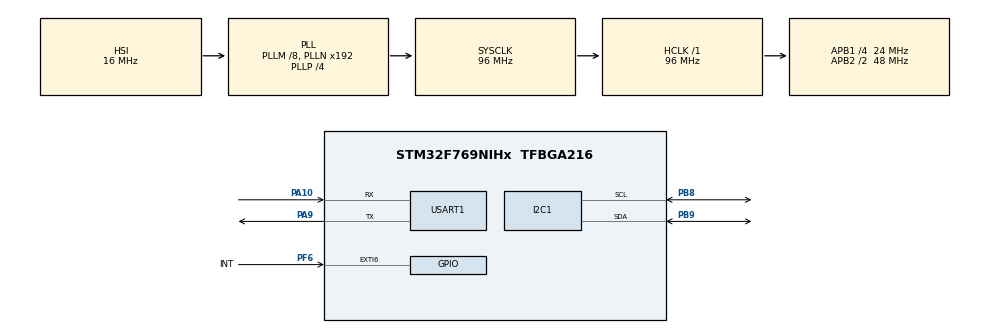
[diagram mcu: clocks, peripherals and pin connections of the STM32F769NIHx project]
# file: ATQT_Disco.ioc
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I2C1.Timing=0x00506682
Mcu.Family=STM32F7
Mcu.Name=STM32F769NIHx
Mcu.Package=TFBGA216
NVIC.EXTI9_5_IRQn=true\:0\:0\:false\:false\:true\:true\:true\:true
NVIC.PriorityGroup=NVIC_PRIORITYGROUP_4
NVIC.TIM5_IRQn=true\:0\:0\:false\:false\:true\:true\:true\:true
PA10.Mode=Asynchronous
PA10.Signal=USART1_RX
PA9.Mode=Asynchronous
PA9.Signal=USART1_TX
PB8.GPIO_Pu=GPIO_PULLUP
PB8.Mode=I2C
PB8.Signal=I2C1_SCL
PB9.GPIO_Pu=GPIO_PULLUP
PB9.Mode=I2C
PB9.Signal=I2C1_SDA
PF6.GPIO_Label=INT
PF6.GPIO_PuPd=GPIO_NOPULL
PF6.Signal=GPXTI6
PH0/OSC_IN.Mode=HSE-External-Oscillator
PH0/OSC_IN.Signal=RCC_OSC_IN
PH1/OSC_OUT.Mode=HSE-External-Oscillator
PH1/OSC_OUT.Signal=RCC_OSC_OUT
ProjectManager.HeapSize=0x200
ProjectManager.StackSize=0x400
ProjectManager.TargetToolchain=STM32CubeIDE
RCC.AHBFreq_Value=96000000
RCC.APB1CLKDivider=RCC_HCLK_DIV4
RCC.APB1Freq_Value=24000000
RCC.APB1TimFreq_Value=48000000
RCC.APB2CLKDivider=RCC_HCLK_DIV2
RCC.APB2Freq_Value=48000000
RCC.APB2TimFreq_Value=96000000
RCC.CortexFreq_Value=96000000
RCC.HCLKFreq_Value=96000000
RCC.HSE_VALUE=25000000
RCC.HSI_VALUE=16000000
RCC.LSE_VALUE=32768
RCC.PLLM=8
RCC.PLLP=RCC_PLLP_DIV4
RCC.PLLQ=4
RCC.PLLSAIQ=3
RCC.SYSCLKFreq_VALUE=96000000
RCC.SYSCLKSource=RCC_SYSCLKSOURCE_PLLCLK
RCC.USBFreq_Value=96000000
RCC.VCOOutputFreq_Value=384000000
TIM2.AutoReloadPreload=TIM_AUTORELOAD_PRELOAD_DISABLE
TIM2.Period=4294967296-1
TIM2.Prescaler=48000-1
TIM5.AutoReloadPreload=TIM_AUTORELOAD_PRELOAD_ENABLE
TIM5.Period=20-1
TIM5.Prescaler=48000-1
USART1.VirtualMode-Asynchronous=VM_ASYNC
VP_TIM2_VS_ClockSourceINT.Mode=Internal
VP_TIM5_VS_ClockSourceINT.Mode=Internal
board=STM32F769I-DISCO

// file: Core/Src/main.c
/* USER CODE BEGIN Header */
/**
  ******************************************************************************
  * @file           : main.c
  * @brief          : Main program body
  ******************************************************************************
  * @attention
  *
  * Copyright (c) 2022 STMicroelectronics.
  * All rights reserved.
  *
  * This software is licensed under terms that can be found in the LICENSE file
  * in the root directory of this software component.
  * If no LICENSE file comes with this software, it is provided AS-IS.
  *
  ******************************************************************************
  */
/* USER CODE END Header */
#include "main.h"
#include "i2c.h"
#include "tim.h"
#include "usart.h"
#include "gpio.h"

/* USER CODE BEGIN Includes */

//#include "Arg_mvp_Qtouch.h"

#include "at42qt2120.h"
/* USER CODE END Includes */

void SystemClock_Config(void);

int main(void)
{

  /* MCU Configuration--------------------------------------------------------*/

  /* Reset of all peripherals, Initializes the Flash interface and the Systick. */
  HAL_Init();

  /* Configure the system clock */
  SystemClock_Config();

  /* Initialize all configured peripherals */
  MX_GPIO_Init();
  MX_I2C1_Init();
  MX_USART1_UART_Init();
  MX_TIM2_Init();
  MX_TIM5_Init();
  /* USER CODE BEGIN 2 */

  //touch sensor init function
  touchSensor_Init();

 HAL_TIM_Base_Start(&htim2);
 HAL_TIM_Base_Start_IT(&htim5);

  /* printf("QTouch test\r\n");
   QTouch_Init();*/

  /* USER CODE END 2 */

  /* Infinite loop */
  while (1)
  {

	}
}

void SystemClock_Config(void)
{
  RCC_OscInitTypeDef RCC_OscInitStruct = {0};
  RCC_ClkInitTypeDef RCC_ClkInitStruct = {0};

  /** Configure the main internal regulator output voltage
  */
  __HAL_RCC_PWR_CLK_ENABLE();
  __HAL_PWR_VOLTAGESCALING_CONFIG(PWR_REGULATOR_VOLTAGE_SCALE3);

  /** Initializes the RCC Oscillators according to the specified parameters
  * in the RCC_OscInitTypeDef structure.
  */
  RCC_OscInitStruct.OscillatorType = RCC_OSCILLATORTYPE_HSI;
  RCC_OscInitStruct.HSIState = RCC_HSI_ON;
  RCC_OscInitStruct.HSICalibrationValue = RCC_HSICALIBRATION_DEFAULT;
  RCC_OscInitStruct.PLL.PLLState = RCC_PLL_ON;
  RCC_OscInitStruct.PLL.PLLSource = RCC_PLLSOURCE_HSI;
  RCC_OscInitStruct.PLL.PLLM = 8;
  RCC_OscInitStruct.PLL.PLLN = 192;
  RCC_OscInitStruct.PLL.PLLP = RCC_PLLP_DIV4;
  RCC_OscInitStruct.PLL.PLLQ = 4;
  RCC_OscInitStruct.PLL.PLLR = 2;
  if (HAL_RCC_OscConfig(&RCC_OscInitStruct) != HAL_OK)
  {
    Error_Handler();
  }

  /** Initializes the CPU, AHB and APB buses clocks
  */
  RCC_ClkInitStruct.ClockType = RCC_CLOCKTYPE_HCLK|RCC_CLOCKTYPE_SYSCLK
                              |RCC_CLOCKTYPE_PCLK1|RCC_CLOCKTYPE_PCLK2;
  RCC_ClkInitStruct.SYSCLKSource = RCC_SYSCLKSOURCE_PLLCLK;
  RCC_ClkInitStruct.AHBCLKDivider = RCC_SYSCLK_DIV1;
  RCC_ClkInitStruct.APB1CLKDivider = RCC_HCLK_DIV4;
  RCC_ClkInitStruct.APB2CLKDivider = RCC_HCLK_DIV2;

  if (HAL_RCC_ClockConfig(&RCC_ClkInitStruct, FLASH_LATENCY_3) != HAL_OK)
  {
    Error_Handler();
  }
}

void Error_Handler(void)
{
  __disable_irq();
  while (1)
  {
  }
}
